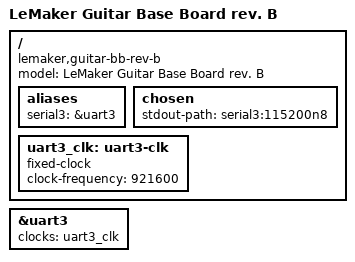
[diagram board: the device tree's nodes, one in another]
/*
 * Copyright (c) 2016-2017 Andreas Färber
 *
 * SPDX-License-Identifier: (GPL-2.0+ OR MIT)
 */

/dts-v1/;

#include "owl-s500-guitar.dtsi"

/ {
	compatible = "lemaker,guitar-bb-rev-b", "lemaker,guitar", "actions,s500";
	model = "LeMaker Guitar Base Board rev. B";

	aliases {
		serial3 = &uart3;
	};

	chosen {
		stdout-path = "serial3:115200n8";
	};

	uart3_clk: uart3-clk {
		compatible = "fixed-clock";
		clock-frequency = <921600>;
		#clock-cells = <0>;
	};
};

&uart3 {
	status = "okay";
	clocks = <&uart3_clk>;
};
